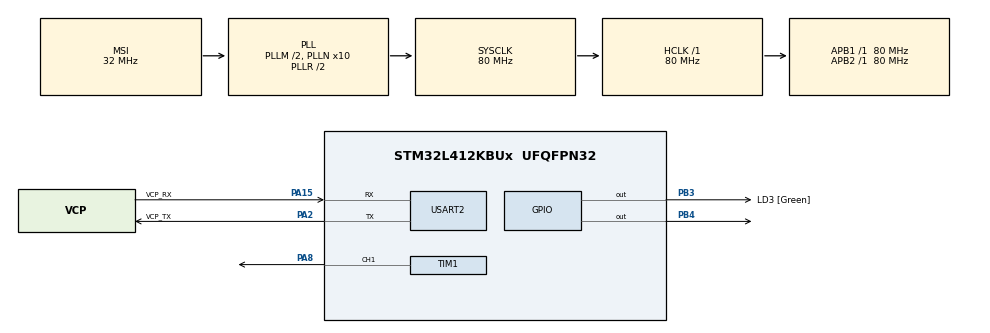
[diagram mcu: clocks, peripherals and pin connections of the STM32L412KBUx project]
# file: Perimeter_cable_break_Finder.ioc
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Mcu.Family=STM32L4
Mcu.Name=STM32L412KBUx
Mcu.Package=UFQFPN32
NVIC.PriorityGroup=NVIC_PRIORITYGROUP_4
PA0-CK_IN.Mode=HSE-External-Clock-Source-for-LittleOrca
PA0-CK_IN.Signal=RCC_CK_IN
PA13\ (JTMS/SWDIO).GPIO_Label=SWDIO
PA13\ (JTMS/SWDIO).Mode=Serial_Wire
PA13\ (JTMS/SWDIO).Signal=SYS_JTMS-SWDIO
PA14\ (JTCK/SWCLK).GPIO_Label=SWCLK
PA14\ (JTCK/SWCLK).Mode=Serial_Wire
PA14\ (JTCK/SWCLK).Signal=SYS_JTCK-SWCLK
PA15\ (JTDI).GPIO_Label=VCP_RX
PA15\ (JTDI).Mode=Asynchronous
PA15\ (JTDI).Signal=USART2_RX
PA2.GPIO_Label=VCP_TX
PA2.Mode=Asynchronous
PA2.Signal=USART2_TX
PA8.GPIO_Speed=GPIO_SPEED_FREQ_HIGH
PA8.Signal=S_TIM1_CH1
PB3\ (JTDO/TRACESWO).GPIO_Label=LD3 [Green]
PB3\ (JTDO/TRACESWO).Signal=GPIO_Output
PB4\ (NJTRST).Signal=GPIO_Output
PC14-OSC32_IN\ (PC14).Mode=LSE-External-Oscillator
PC14-OSC32_IN\ (PC14).Signal=RCC_OSC32_IN
PC15-OSC32_OUT\ (PC15).Mode=LSE-External-Oscillator
PC15-OSC32_OUT\ (PC15).Signal=RCC_OSC32_OUT
ProjectManager.HeapSize=0x200
ProjectManager.StackSize=0x400
ProjectManager.TargetToolchain=STM32CubeIDE
RCC.ADCFreq_Value=80000000
RCC.AHBFreq_Value=80000000
RCC.APB1Freq_Value=80000000
RCC.APB1TimFreq_Value=80000000
RCC.APB2Freq_Value=80000000
RCC.APB2TimFreq_Value=80000000
RCC.CortexFreq_Value=80000000
RCC.FLatency=FLASH_LATENCY_4
RCC.HCLKFreq_Value=80000000
RCC.HSE_VALUE=8000000
RCC.HSI48_VALUE=48000000
RCC.HSICalibrationValue=16
RCC.HSI_VALUE=16000000
RCC.MSIClockRange=RCC_MSIRANGE_10
RCC.MSI_VALUE=32000000
RCC.PLLM=2
RCC.PLLN=10
RCC.SYSCLKFreq_VALUE=80000000
RCC.SYSCLKSource=RCC_SYSCLKSOURCE_PLLCLK
RCC.USBFreq_Value=32000000
RCC.VCOOutputFreq_Value=160000000
SH.S_TIM1_CH1.0=TIM1_CH1,PWM Generation1 CH1
TIM1.AutoReloadPreload=TIM_AUTORELOAD_PRELOAD_ENABLE
TIM1.Channel-PWM\ Generation1\ CH1=TIM_CHANNEL_1
TIM1.Period=800
TIM1.Pulse-PWM\ Generation1\ CH1=400
USART2.VirtualMode-Asynchronous=VM_ASYNC
board=NUCLEO-L412KB

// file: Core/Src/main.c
/* USER CODE BEGIN Header */
/**
  ******************************************************************************
  * @file           : main.c
  * @brief          : Main program body
  ******************************************************************************
  * @attention
  *
  * Copyright (c) 2023 STMicroelectronics.
  * All rights reserved.
  *
  * This software is licensed under terms that can be found in the LICENSE file
  * in the root directory of this software component.
  * If no LICENSE file comes with this software, it is provided AS-IS.
  *
  ******************************************************************************
  */
/* USER CODE END Header */
#include "main.h"

TIM_HandleTypeDef htim1;

UART_HandleTypeDef huart2;

void SystemClock_Config(void);
static void MX_GPIO_Init(void);
static void MX_USART2_UART_Init(void);
static void MX_TIM1_Init(void);

int main(void)
{

  /* MCU Configuration--------------------------------------------------------*/

  /* Reset of all peripherals, Initializes the Flash interface and the Systick. */
  HAL_Init();

  /* Configure the system clock */
  SystemClock_Config();

  /* Initialize all configured peripherals */
  MX_GPIO_Init();
  MX_USART2_UART_Init();
  MX_TIM1_Init();
  /* USER CODE BEGIN 2 */

  HAL_GPIO_WritePin(LD3_GPIO_Port,LD3_Pin,GPIO_PIN_RESET);
  HAL_Delay(2000);
  /* USER CODE END 2 */

  /* Infinite loop */
  /* USER CODE BEGIN WHILE */

  while (1)
  {
	  HAL_GPIO_TogglePin(LD3_GPIO_Port,LD3_Pin);
	  HAL_TIM_PWM_Start(&htim1,TIM_CHANNEL_1);
	  HAL_Delay(500);

	  HAL_GPIO_TogglePin(LD3_GPIO_Port,LD3_Pin);
	  HAL_TIM_PWM_Stop(&htim1,TIM_CHANNEL_1);
	  HAL_Delay(500);

    /* USER CODE END WHILE */

  }
}

void SystemClock_Config(void)
{
  RCC_OscInitTypeDef RCC_OscInitStruct = {0};
  RCC_ClkInitTypeDef RCC_ClkInitStruct = {0};

  /** Configure the main internal regulator output voltage
  */
  if (HAL_PWREx_ControlVoltageScaling(PWR_REGULATOR_VOLTAGE_SCALE1) != HAL_OK)
  {
    Error_Handler();
  }

  /** Configure LSE Drive Capability
  */
  HAL_PWR_EnableBkUpAccess();
  __HAL_RCC_LSEDRIVE_CONFIG(RCC_LSEDRIVE_LOW);

  /** Initializes the RCC Oscillators according to the specified parameters
  * in the RCC_OscInitTypeDef structure.
  */
  RCC_OscInitStruct.OscillatorType = RCC_OSCILLATORTYPE_LSE|RCC_OSCILLATORTYPE_MSI;
  RCC_OscInitStruct.LSEState = RCC_LSE_ON;
  RCC_OscInitStruct.MSIState = RCC_MSI_ON;
  RCC_OscInitStruct.MSICalibrationValue = 0;
  RCC_OscInitStruct.MSIClockRange = RCC_MSIRANGE_10;
  RCC_OscInitStruct.PLL.PLLState = RCC_PLL_ON;
  RCC_OscInitStruct.PLL.PLLSource = RCC_PLLSOURCE_MSI;
  RCC_OscInitStruct.PLL.PLLM = 2;
  RCC_OscInitStruct.PLL.PLLN = 10;
  RCC_OscInitStruct.PLL.PLLQ = RCC_PLLQ_DIV2;
  RCC_OscInitStruct.PLL.PLLR = RCC_PLLR_DIV2;
  if (HAL_RCC_OscConfig(&RCC_OscInitStruct) != HAL_OK)
  {
    Error_Handler();
  }

  /** Initializes the CPU, AHB and APB buses clocks
  */
  RCC_ClkInitStruct.ClockType = RCC_CLOCKTYPE_HCLK|RCC_CLOCKTYPE_SYSCLK
                              |RCC_CLOCKTYPE_PCLK1|RCC_CLOCKTYPE_PCLK2;
  RCC_ClkInitStruct.SYSCLKSource = RCC_SYSCLKSOURCE_PLLCLK;
  RCC_ClkInitStruct.AHBCLKDivider = RCC_SYSCLK_DIV1;
  RCC_ClkInitStruct.APB1CLKDivider = RCC_HCLK_DIV1;
  RCC_ClkInitStruct.APB2CLKDivider = RCC_HCLK_DIV1;

  if (HAL_RCC_ClockConfig(&RCC_ClkInitStruct, FLASH_LATENCY_4) != HAL_OK)
  {
    Error_Handler();
  }

  /** Enable MSI Auto calibration
  */
  HAL_RCCEx_EnableMSIPLLMode();
}

static void MX_TIM1_Init(void)
{

  TIM_MasterConfigTypeDef sMasterConfig = {0};
  TIM_OC_InitTypeDef sConfigOC = {0};
  TIM_BreakDeadTimeConfigTypeDef sBreakDeadTimeConfig = {0};

  htim1.Instance = TIM1;
  htim1.Init.Prescaler = 0;
  htim1.Init.CounterMode = TIM_COUNTERMODE_UP;
  htim1.Init.Period = 298;
  htim1.Init.ClockDivision = TIM_CLOCKDIVISION_DIV1;
  htim1.Init.RepetitionCounter = 0;
  htim1.Init.AutoReloadPreload = TIM_AUTORELOAD_PRELOAD_ENABLE;
  if (HAL_TIM_PWM_Init(&htim1) != HAL_OK)
  {
    Error_Handler();
  }
  sMasterConfig.MasterOutputTrigger = TIM_TRGO_RESET;
  sMasterConfig.MasterOutputTrigger2 = TIM_TRGO2_RESET;
  sMasterConfig.MasterSlaveMode = TIM_MASTERSLAVEMODE_DISABLE;
  if (HAL_TIMEx_MasterConfigSynchronization(&htim1, &sMasterConfig) != HAL_OK)
  {
    Error_Handler();
  }
  sConfigOC.OCMode = TIM_OCMODE_PWM1;
  sConfigOC.Pulse = 3;
  sConfigOC.OCPolarity = TIM_OCPOLARITY_HIGH;
  sConfigOC.OCNPolarity = TIM_OCNPOLARITY_HIGH;
  sConfigOC.OCFastMode = TIM_OCFAST_DISABLE;
  sConfigOC.OCIdleState = TIM_OCIDLESTATE_RESET;
  sConfigOC.OCNIdleState = TIM_OCNIDLESTATE_RESET;
  if (HAL_TIM_PWM_ConfigChannel(&htim1, &sConfigOC, TIM_CHANNEL_1) != HAL_OK)
  {
    Error_Handler();
  }
  sBreakDeadTimeConfig.OffStateRunMode = TIM_OSSR_DISABLE;
  sBreakDeadTimeConfig.OffStateIDLEMode = TIM_OSSI_DISABLE;
  sBreakDeadTimeConfig.LockLevel = TIM_LOCKLEVEL_OFF;
  sBreakDeadTimeConfig.DeadTime = 0;
  sBreakDeadTimeConfig.BreakState = TIM_BREAK_DISABLE;
  sBreakDeadTimeConfig.BreakPolarity = TIM_BREAKPOLARITY_HIGH;
  sBreakDeadTimeConfig.BreakFilter = 0;
  sBreakDeadTimeConfig.Break2State = TIM_BREAK2_DISABLE;
  sBreakDeadTimeConfig.Break2Polarity = TIM_BREAK2POLARITY_HIGH;
  sBreakDeadTimeConfig.Break2Filter = 0;
  sBreakDeadTimeConfig.AutomaticOutput = TIM_AUTOMATICOUTPUT_DISABLE;
  if (HAL_TIMEx_ConfigBreakDeadTime(&htim1, &sBreakDeadTimeConfig) != HAL_OK)
  {
    Error_Handler();
  }
  HAL_TIM_MspPostInit(&htim1);

}

static void MX_USART2_UART_Init(void)
{

  huart2.Instance = USART2;
  huart2.Init.BaudRate = 115200;
  huart2.Init.WordLength = UART_WORDLENGTH_8B;
  huart2.Init.StopBits = UART_STOPBITS_1;
  huart2.Init.Parity = UART_PARITY_NONE;
  huart2.Init.Mode = UART_MODE_TX_RX;
  huart2.Init.HwFlowCtl = UART_HWCONTROL_NONE;
  huart2.Init.OverSampling = UART_OVERSAMPLING_16;
  huart2.Init.OneBitSampling = UART_ONE_BIT_SAMPLE_DISABLE;
  huart2.AdvancedInit.AdvFeatureInit = UART_ADVFEATURE_NO_INIT;
  if (HAL_UART_Init(&huart2) != HAL_OK)
  {
    Error_Handler();
  }

}

static void MX_GPIO_Init(void)
{
  GPIO_InitTypeDef GPIO_InitStruct = {0};

  /* GPIO Ports Clock Enable */
  __HAL_RCC_GPIOC_CLK_ENABLE();
  __HAL_RCC_GPIOA_CLK_ENABLE();
  __HAL_RCC_GPIOB_CLK_ENABLE();

  /*Configure GPIO pin Output Level */
  HAL_GPIO_WritePin(GPIOB, LD3_Pin|GPIO_PIN_4, GPIO_PIN_RESET);

  /*Configure GPIO pins : LD3_Pin PB4 */
  GPIO_InitStruct.Pin = LD3_Pin|GPIO_PIN_4;
  GPIO_InitStruct.Mode = GPIO_MODE_OUTPUT_PP;
  GPIO_InitStruct.Pull = GPIO_NOPULL;
  GPIO_InitStruct.Speed = GPIO_SPEED_FREQ_LOW;
  HAL_GPIO_Init(GPIOB, &GPIO_InitStruct);

}

void Error_Handler(void)
{
  __disable_irq();
  while (1)
  {
  }
}
